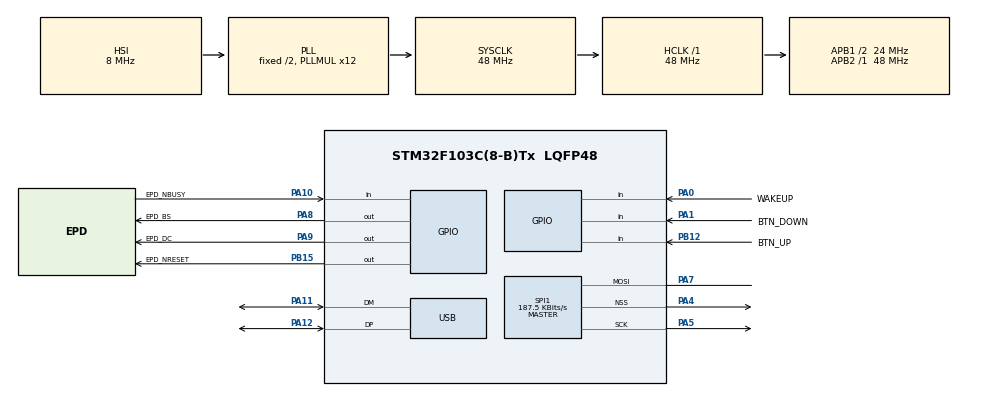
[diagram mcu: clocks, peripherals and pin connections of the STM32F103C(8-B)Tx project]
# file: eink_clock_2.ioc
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Mcu.Family=STM32F1
Mcu.Name=STM32F103C(8-B)Tx
Mcu.Package=LQFP48
NVIC.PriorityGroup=NVIC_PRIORITYGROUP_4
NVIC.RTC_Alarm_IRQn=true\:0\:0\:false\:false\:true\:true\:true\:true
NVIC.SPI1_IRQn=true\:3\:0\:true\:false\:true\:true\:true\:true
PA0-WKUP.GPIO_Label=WAKEUP
PA0-WKUP.Signal=GPIO_Input
PA1.GPIO_Label=BTN_DOWN
PA1.Signal=GPIO_Input
PA10.GPIO_Label=EPD_NBUSY
PA10.GPIO_PuPd=GPIO_PULLUP
PA10.Signal=GPIO_Input
PA11.Mode=Device
PA11.Signal=USB_DM
PA12.Mode=Device
PA12.Signal=USB_DP
PA4.Mode=NSS_Signal_Hard_Output
PA4.Signal=SPI1_NSS
PA5.Mode=Simplex_Bidirectional_Master
PA5.Signal=SPI1_SCK
PA7.Mode=Simplex_Bidirectional_Master
PA7.Signal=SPI1_MOSI
PA8.GPIO_Label=EPD_BS
PA8.Signal=GPIO_Output
PA9.GPIO_Label=EPD_DC
PA9.Signal=GPIO_Output
PB12.GPIO_Label=BTN_UP
PB12.Signal=GPIO_Input
PB15.GPIO_Label=EPD_NRESET
PB15.GPIO_PuPd=GPIO_PULLUP
PB15.Signal=GPIO_Output
PC14-OSC32_IN.Mode=LSE-External-Oscillator
PC14-OSC32_IN.Signal=RCC_OSC32_IN
PC15-OSC32_OUT.Mode=LSE-External-Oscillator
PC15-OSC32_OUT.Signal=RCC_OSC32_OUT
ProjectManager.HeapSize=0x200
ProjectManager.StackSize=0x400
ProjectManager.TargetToolchain=STM32CubeIDE
RCC.AHBFreq_Value=48000000
RCC.APB1CLKDivider=RCC_HCLK_DIV2
RCC.APB1Freq_Value=24000000
RCC.APB1TimFreq_Value=48000000
RCC.APB2Freq_Value=48000000
RCC.APB2TimFreq_Value=48000000
RCC.HCLKFreq_Value=48000000
RCC.PLLMUL=RCC_PLL_MUL12
RCC.PLLSource=RCC_PLLSOURCE_HSI_DIV2
RCC.PLLSourceVirtual=RCC_PLLSOURCE_HSI_DIV2
RCC.RTCClockSelection=RCC_RTCCLKSOURCE_LSE
RCC.SYSCLKFreq_VALUE=48000000
RCC.SYSCLKSource=RCC_SYSCLKSOURCE_PLLCLK
RCC.USBFreq_Value=48000000
SPI1.BaudRatePrescaler=SPI_BAUDRATEPRESCALER_256
SPI1.CalculateBaudRate=187.5 KBits/s
SPI1.Direction=SPI_DIRECTION_1LINE
SPI1.Mode=SPI_MODE_MASTER
SPI1.VirtualNSS=VM_NSSHARD
SPI1.VirtualType=VM_MASTER
VP_RTC_VS_RTC_Activate.Mode=RTC_Enabled
VP_RTC_VS_RTC_Calendar.Mode=RTC_Calendar
VP_SYS_VS_ND.Mode=No_Debug
board=custom

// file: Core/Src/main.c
/* USER CODE BEGIN Header */
/**
  ******************************************************************************
  * @file           : main.c
  * @brief          : Main program body
  ******************************************************************************
  * @attention
  *
  * Copyright (c) 2024 STMicroelectronics.
  * All rights reserved.
  *
  * This software is licensed under terms that can be found in the LICENSE file
  * in the root directory of this software component.
  * If no LICENSE file comes with this software, it is provided AS-IS.
  *
  ******************************************************************************
  */
/* USER CODE END Header */
#include "main.h"

/* USER CODE BEGIN Includes */
#include "ClockMain.h"

/* USER CODE END Includes */

RTC_HandleTypeDef hrtc;

SPI_HandleTypeDef hspi1;

PCD_HandleTypeDef hpcd_USB_FS;

void SystemClock_Config(void);
static void MX_GPIO_Init(void);
static void MX_SPI1_Init(void);
static void MX_RTC_Init(void);
static void MX_USB_PCD_Init(void);

int main(void)
{

  /* MCU Configuration--------------------------------------------------------*/

  /* Reset of all peripherals, Initializes the Flash interface and the Systick. */
  HAL_Init();

  /* Configure the system clock */
  SystemClock_Config();

  /* Initialize all configured peripherals */
  MX_GPIO_Init();
  MX_SPI1_Init();
  MX_RTC_Init();
  MX_USB_PCD_Init();

  /* Infinite loop */
  while (1)
  {

    /* USER CODE BEGIN 3 */
	  ClockMain();
  }
  /* USER CODE END 3 */
}

void SystemClock_Config(void)
{
  RCC_OscInitTypeDef RCC_OscInitStruct = {0};
  RCC_ClkInitTypeDef RCC_ClkInitStruct = {0};
  RCC_PeriphCLKInitTypeDef PeriphClkInit = {0};

  /** Initializes the RCC Oscillators according to the specified parameters
  * in the RCC_OscInitTypeDef structure.
  */
  RCC_OscInitStruct.OscillatorType = RCC_OSCILLATORTYPE_HSI|RCC_OSCILLATORTYPE_LSE;
  RCC_OscInitStruct.LSEState = RCC_LSE_ON;
  RCC_OscInitStruct.HSIState = RCC_HSI_ON;
  RCC_OscInitStruct.HSICalibrationValue = RCC_HSICALIBRATION_DEFAULT;
  RCC_OscInitStruct.PLL.PLLState = RCC_PLL_ON;
  RCC_OscInitStruct.PLL.PLLSource = RCC_PLLSOURCE_HSI_DIV2;
  RCC_OscInitStruct.PLL.PLLMUL = RCC_PLL_MUL12;
  if (HAL_RCC_OscConfig(&RCC_OscInitStruct) != HAL_OK)
  {
    Error_Handler();
  }

  /** Initializes the CPU, AHB and APB buses clocks
  */
  RCC_ClkInitStruct.ClockType = RCC_CLOCKTYPE_HCLK|RCC_CLOCKTYPE_SYSCLK
                              |RCC_CLOCKTYPE_PCLK1|RCC_CLOCKTYPE_PCLK2;
  RCC_ClkInitStruct.SYSCLKSource = RCC_SYSCLKSOURCE_PLLCLK;
  RCC_ClkInitStruct.AHBCLKDivider = RCC_SYSCLK_DIV1;
  RCC_ClkInitStruct.APB1CLKDivider = RCC_HCLK_DIV2;
  RCC_ClkInitStruct.APB2CLKDivider = RCC_HCLK_DIV1;

  if (HAL_RCC_ClockConfig(&RCC_ClkInitStruct, FLASH_LATENCY_1) != HAL_OK)
  {
    Error_Handler();
  }
  PeriphClkInit.PeriphClockSelection = RCC_PERIPHCLK_RTC|RCC_PERIPHCLK_USB;
  PeriphClkInit.RTCClockSelection = RCC_RTCCLKSOURCE_LSE;
  PeriphClkInit.UsbClockSelection = RCC_USBCLKSOURCE_PLL;
  if (HAL_RCCEx_PeriphCLKConfig(&PeriphClkInit) != HAL_OK)
  {
    Error_Handler();
  }
}

static void MX_RTC_Init(void)
{

  RTC_TimeTypeDef sTime = {0};
  RTC_DateTypeDef DateToUpdate = {0};

  /** Initialize RTC Only
  */
  hrtc.Instance = RTC;
  hrtc.Init.AsynchPrediv = RTC_AUTO_1_SECOND;
  hrtc.Init.OutPut = RTC_OUTPUTSOURCE_ALARM;
  if (HAL_RTC_Init(&hrtc) != HAL_OK)
  {
    Error_Handler();
  }

  /** Initialize RTC and set the Time and Date
  */
  sTime.Hours = 0x0;
  sTime.Minutes = 0x0;
  sTime.Seconds = 0x0;

  if (HAL_RTC_SetTime(&hrtc, &sTime, RTC_FORMAT_BCD) != HAL_OK)
  {
    Error_Handler();
  }
  DateToUpdate.WeekDay = RTC_WEEKDAY_MONDAY;
  DateToUpdate.Month = RTC_MONTH_JANUARY;
  DateToUpdate.Date = 0x1;
  DateToUpdate.Year = 0x0;

  if (HAL_RTC_SetDate(&hrtc, &DateToUpdate, RTC_FORMAT_BCD) != HAL_OK)
  {
    Error_Handler();
  }

}

static void MX_SPI1_Init(void)
{

  /* SPI1 parameter configuration*/
  hspi1.Instance = SPI1;
  hspi1.Init.Mode = SPI_MODE_MASTER;
  hspi1.Init.Direction = SPI_DIRECTION_1LINE;
  hspi1.Init.DataSize = SPI_DATASIZE_8BIT;
  hspi1.Init.CLKPolarity = SPI_POLARITY_LOW;
  hspi1.Init.CLKPhase = SPI_PHASE_1EDGE;
  hspi1.Init.NSS = SPI_NSS_HARD_OUTPUT;
  hspi1.Init.BaudRatePrescaler = SPI_BAUDRATEPRESCALER_256;
  hspi1.Init.FirstBit = SPI_FIRSTBIT_MSB;
  hspi1.Init.TIMode = SPI_TIMODE_DISABLE;
  hspi1.Init.CRCCalculation = SPI_CRCCALCULATION_DISABLE;
  hspi1.Init.CRCPolynomial = 10;
  if (HAL_SPI_Init(&hspi1) != HAL_OK)
  {
    Error_Handler();
  }

}

static void MX_USB_PCD_Init(void)
{

  hpcd_USB_FS.Instance = USB;
  hpcd_USB_FS.Init.dev_endpoints = 8;
  hpcd_USB_FS.Init.speed = PCD_SPEED_FULL;
  hpcd_USB_FS.Init.low_power_enable = DISABLE;
  hpcd_USB_FS.Init.lpm_enable = DISABLE;
  hpcd_USB_FS.Init.battery_charging_enable = DISABLE;
  if (HAL_PCD_Init(&hpcd_USB_FS) != HAL_OK)
  {
    Error_Handler();
  }

}

static void MX_GPIO_Init(void)
{
  GPIO_InitTypeDef GPIO_InitStruct = {0};

  /* GPIO Ports Clock Enable */
  __HAL_RCC_GPIOC_CLK_ENABLE();
  __HAL_RCC_GPIOA_CLK_ENABLE();
  __HAL_RCC_GPIOB_CLK_ENABLE();

  /*Configure GPIO pin Output Level */
  HAL_GPIO_WritePin(EPD_NRESET_GPIO_Port, EPD_NRESET_Pin, GPIO_PIN_RESET);

  /*Configure GPIO pin Output Level */
  HAL_GPIO_WritePin(GPIOA, EPD_BS_Pin|EPD_DC_Pin, GPIO_PIN_RESET);

  /*Configure GPIO pins : WAKEUP_Pin BTN_DOWN_Pin */
  GPIO_InitStruct.Pin = WAKEUP_Pin|BTN_DOWN_Pin;
  GPIO_InitStruct.Mode = GPIO_MODE_INPUT;
  GPIO_InitStruct.Pull = GPIO_NOPULL;
  HAL_GPIO_Init(GPIOA, &GPIO_InitStruct);

  /*Configure GPIO pin : BTN_UP_Pin */
  GPIO_InitStruct.Pin = BTN_UP_Pin;
  GPIO_InitStruct.Mode = GPIO_MODE_INPUT;
  GPIO_InitStruct.Pull = GPIO_NOPULL;
  HAL_GPIO_Init(BTN_UP_GPIO_Port, &GPIO_InitStruct);

  /*Configure GPIO pin : EPD_NRESET_Pin */
  GPIO_InitStruct.Pin = EPD_NRESET_Pin;
  GPIO_InitStruct.Mode = GPIO_MODE_OUTPUT_PP;
  GPIO_InitStruct.Pull = GPIO_PULLUP;
  GPIO_InitStruct.Speed = GPIO_SPEED_FREQ_LOW;
  HAL_GPIO_Init(EPD_NRESET_GPIO_Port, &GPIO_InitStruct);

  /*Configure GPIO pins : EPD_BS_Pin EPD_DC_Pin */
  GPIO_InitStruct.Pin = EPD_BS_Pin|EPD_DC_Pin;
  GPIO_InitStruct.Mode = GPIO_MODE_OUTPUT_PP;
  GPIO_InitStruct.Pull = GPIO_NOPULL;
  GPIO_InitStruct.Speed = GPIO_SPEED_FREQ_LOW;
  HAL_GPIO_Init(GPIOA, &GPIO_InitStruct);

  /*Configure GPIO pin : EPD_NBUSY_Pin */
  GPIO_InitStruct.Pin = EPD_NBUSY_Pin;
  GPIO_InitStruct.Mode = GPIO_MODE_INPUT;
  GPIO_InitStruct.Pull = GPIO_PULLUP;
  HAL_GPIO_Init(EPD_NBUSY_GPIO_Port, &GPIO_InitStruct);

}

void Error_Handler(void)
{
  __disable_irq();
  while (1)
  {
  }
}
